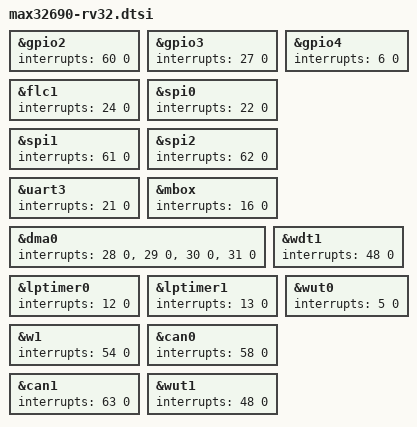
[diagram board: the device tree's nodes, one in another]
/*
 * Copyright (c) 2023-2026 Analog Devices, Inc.
 *
 * SPDX-License-Identifier: Apache-2.0
 */

#include <adi/max32/max32690.dtsi>
#include <adi/max32/max32xxx-rv32.dtsi>

&gpio2 {
	interrupts = <60 0>;
};

&gpio3 {
	interrupts = <27 0>;
};

&gpio4 {
	interrupts = <6 0>;
};

&flc1 {
	interrupts = <24 0>;
};

&spi0 {
	interrupts = <22 0>;
};

&spi1 {
	interrupts = <61 0>;
};

&spi2 {
	interrupts = <62 0>;
};

&uart3 {
	interrupts = <21 0>;
};

&mbox {
	interrupts = <16 0>;
};

&dma0 {
	interrupts = <28 0>, <29 0>, <30 0>, <31 0>;
};

&wdt1 {
	interrupts = <48 0>;
};

&lptimer0 {
	interrupts = <12 0>;
};

&lptimer1 {
	interrupts = <13 0>;
};

&w1 {
	interrupts = <54 0>;
};

&can0 {
	interrupts = <58 0>;
};

&can1 {
	interrupts = <63 0>;
};

&wut0 {
	interrupts = <5 0>;
};

&wut1 {
	interrupts = <48 0>;
};
